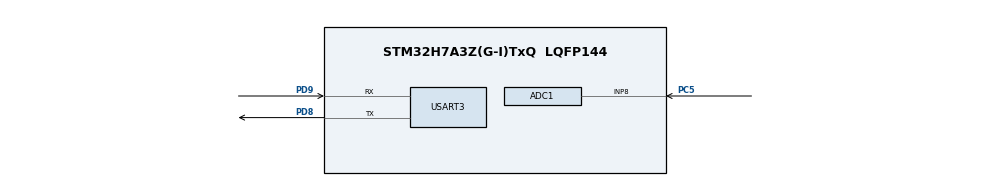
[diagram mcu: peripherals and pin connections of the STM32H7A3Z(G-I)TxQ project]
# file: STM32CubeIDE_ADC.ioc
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ADC1.Channel-4\#ChannelRegularConversion=ADC_CHANNEL_8
ADC1.ContinuousConvMode=ENABLE
ADC1.NbrOfConversionFlag=1
ADC1.OffsetNumber-4\#ChannelRegularConversion=ADC_OFFSET_NONE
ADC1.OffsetSignedSaturation-4\#ChannelRegularConversion=DISABLE
ADC1.Rank-4\#ChannelRegularConversion=1
ADC1.SamplingTime-4\#ChannelRegularConversion=ADC_SAMPLETIME_1CYCLE_5
ADC1.master=1
Mcu.Family=STM32H7
Mcu.Name=STM32H7A3Z(G-I)TxQ
Mcu.Package=LQFP144
NVIC.PriorityGroup=NVIC_PRIORITYGROUP_4
PC5.Signal=ADCx_INP8
PD8.Mode=Asynchronous
PD8.Signal=USART3_TX
PD9.Mode=Asynchronous
PD9.Signal=USART3_RX
PH0-OSC_IN.Mode=HSE-External-Oscillator
PH0-OSC_IN.Signal=RCC_OSC_IN
PH1-OSC_OUT.Mode=HSE-External-Oscillator
PH1-OSC_OUT.Signal=RCC_OSC_OUT
ProjectManager.HeapSize=0x200
ProjectManager.StackSize=0x400
ProjectManager.TargetToolchain=STM32CubeIDE
RCC.ADCFreq_Value=128000000
RCC.APB1Freq_Value=32000000
RCC.APB2Freq_Value=32000000
RCC.APB3Freq_Value=32000000
RCC.APB4Freq_Value=32000000
RCC.CDPPRE=RCC_APB3_DIV2
RCC.CDPPRE1=RCC_APB1_DIV2
RCC.CDPPRE2=RCC_APB2_DIV2
RCC.CortexFreq_Value=64000000
RCC.DIVM2=4
RCC.DIVN2=8
RCC.DIVP2=1
RCC.EnableLSERTC-ClockTree=true
RCC.HCLKFreq_Value=64000000
RCC.PLL2FRACN=0
RCC.SRDPPRE=RCC_APB4_DIV2
RCC.SYSCLKFreq_VALUE=64000000
RCC.USBFreq_Value=129000000
SH.ADCx_INP8.0=ADC1_INP8,IN8-Single-Ended
USART3.VirtualMode-Asynchronous=VM_ASYNC
board=custom

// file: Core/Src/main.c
/* USER CODE BEGIN Header */
/**
  ******************************************************************************
  * @file           : main.c
  * @brief          : Main program body
  ******************************************************************************
  * @attention
  *
  * Copyright (c) 2023 STMicroelectronics.
  * All rights reserved.
  *
  * This software is licensed under terms that can be found in the LICENSE file
  * in the root directory of this software component.
  * If no LICENSE file comes with this software, it is provided AS-IS.
  *
  ******************************************************************************
  */
/* USER CODE END Header */
#include "main.h"
#include "adc.h"
#include "usart.h"
#include "gpio.h"

/* USER CODE BEGIN Includes */
#include "stdio.h"
#include <stdbool.h>
/* USER CODE END Includes */

/* USER CODE BEGIN PM */
#ifdef __GNUC__
#define PUTCHAR_PROTOTYPE int __io_putchar(int ch)
#else
#define PUTCHAR_PROTOTYPE int fputc(int ch, FILE *f)
#endif

PUTCHAR_PROTOTYPE{
   HAL_UART_Transmit(&huart3, (uint8_t*)&ch, 1, 0xFFFF);
   return ch;
}
/* USER CODE END PM */

void SystemClock_Config(void);

/* USER CODE BEGIN 0 */
int _write(int file, unsigned char * p, int len){
	HAL_UART_Transmit(&huart3, p, len, 10);
	return len;
}

uint16_t adc_value=0;
/* USER CODE END 0 */

int main(void)
{

  /* MCU Configuration--------------------------------------------------------*/

  /* Reset of all peripherals, Initializes the Flash interface and the Systick. */
   HAL_Init();

  /* Configure the system clock */
  SystemClock_Config();

  /* Initialize all configured peripherals */
  MX_GPIO_Init();
  MX_ADC1_Init();
  MX_USART3_UART_Init();
  /* USER CODE BEGIN 2 */
  HAL_ADC_Start(&hadc1);

  /* USER CODE END 2 */

  /* Infinite loop */
  /* USER CODE BEGIN WHILE */
  while (1)
  {
	  if (HAL_ADC_PollForConversion(&hadc1, 1000000) == HAL_OK) {
	      adc_value = HAL_ADC_GetValue(&hadc1);
	      printf("adc_value = %d\r\n", (int)adc_value);
	    }
	    HAL_Delay(100);
    /* USER CODE END WHILE */

  }
}

void SystemClock_Config(void)
{
  RCC_OscInitTypeDef RCC_OscInitStruct = {0};
  RCC_ClkInitTypeDef RCC_ClkInitStruct = {0};

  /** Supply configuration update enable
  */
  HAL_PWREx_ConfigSupply(PWR_DIRECT_SMPS_SUPPLY);
  /** Configure the main internal regulator output voltage
  */
  __HAL_PWR_VOLTAGESCALING_CONFIG(PWR_REGULATOR_VOLTAGE_SCALE3);

  while(!__HAL_PWR_GET_FLAG(PWR_FLAG_VOSRDY)) {}
  /** Macro to configure the PLL clock source
  */
  __HAL_RCC_PLL_PLLSOURCE_CONFIG(RCC_PLLSOURCE_HSI);
  /** Initializes the RCC Oscillators according to the specified parameters
  * in the RCC_OscInitTypeDef structure.
  */
  RCC_OscInitStruct.OscillatorType = RCC_OSCILLATORTYPE_HSI;
  RCC_OscInitStruct.HSIState = RCC_HSI_DIV1;
  RCC_OscInitStruct.HSICalibrationValue = RCC_HSICALIBRATION_DEFAULT;
  RCC_OscInitStruct.PLL.PLLState = RCC_PLL_NONE;
  RCC_OscInitStruct.PLL.PLLSource = RCC_PLLSOURCE_HSI;
  if (HAL_RCC_OscConfig(&RCC_OscInitStruct) != HAL_OK)
  {
    Error_Handler();
  }
  /** Initializes the CPU, AHB and APB buses clocks
  */
  RCC_ClkInitStruct.ClockType = RCC_CLOCKTYPE_HCLK|RCC_CLOCKTYPE_SYSCLK
                              |RCC_CLOCKTYPE_PCLK1|RCC_CLOCKTYPE_PCLK2
                              |RCC_CLOCKTYPE_D3PCLK1|RCC_CLOCKTYPE_D1PCLK1;
  RCC_ClkInitStruct.SYSCLKSource = RCC_SYSCLKSOURCE_HSI;
  RCC_ClkInitStruct.SYSCLKDivider = RCC_SYSCLK_DIV1;
  RCC_ClkInitStruct.AHBCLKDivider = RCC_HCLK_DIV1;
  RCC_ClkInitStruct.APB3CLKDivider = RCC_APB3_DIV2;
  RCC_ClkInitStruct.APB1CLKDivider = RCC_APB1_DIV2;
  RCC_ClkInitStruct.APB2CLKDivider = RCC_APB2_DIV2;
  RCC_ClkInitStruct.APB4CLKDivider = RCC_APB4_DIV2;

  if (HAL_RCC_ClockConfig(&RCC_ClkInitStruct, FLASH_LATENCY_2) != HAL_OK)
  {
    Error_Handler();
  }
}

void Error_Handler(void)
{
  __disable_irq();
  while (1)
  {
  }
}
